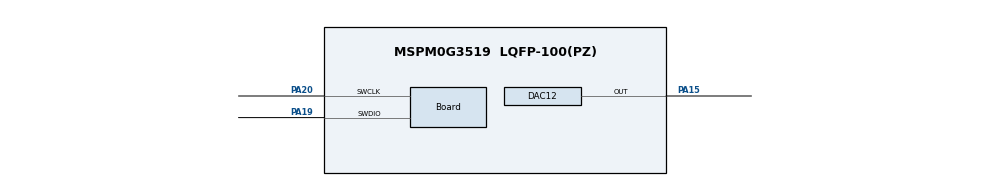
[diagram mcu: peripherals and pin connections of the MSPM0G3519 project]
//@cliArgs --device "MSPM0G351X" --package "LQFP-100(PZ)" --part "Default"
//@v2CliArgs --device "MSPM0G3519" --package "LQFP-100(PZ)"
// @cliArgs --board /ti/boards/LP_MSPM0G3519 --rtos nortos

/**
 * Import the modules used in this configuration.
 */
const DAC12  = scripting.addModule("/ti/driverlib/DAC12");
const SYSCTL = scripting.addModule("/ti/driverlib/SYSCTL");

/**
 * Write custom configuration values to the imported modules.
 */
const gate8  = system.clockTree["MFPCLKGATE"];
gate8.enable = true;

DAC12.dacOutputPinEn            = true;
DAC12.dacAmplifier              = "ON";
DAC12.dacFIFOEn                 = true;
DAC12.dacDMATrigger             = false;
DAC12.dacSampleTimerRate        = "16K";
DAC12.dacEnabledInterrupts      = ["FIFO_TWO_QTRS_EMPTY"];
DAC12.dacOutput12               = 4095;
DAC12.peripheral.$assign        = "DAC0";
DAC12.peripheral.OutPin.$assign = "PA15";

const Board                       = scripting.addModule("/ti/driverlib/Board", {}, false);
Board.peripheral.$assign          = "DEBUGSS";
Board.peripheral.swclkPin.$assign = "PA20";
Board.peripheral.swdioPin.$assign = "PA19";

SYSCTL.MFPCLKEn              = true;
SYSCTL.enableSleepOnExit     = true;
SYSCTL.forceDefaultClkConfig = true;
SYSCTL.clockTreeEn           = true;

const ProjectConfig              = scripting.addModule("/ti/project_config/ProjectConfig", {}, false);
ProjectConfig.migrationCondition = true;
